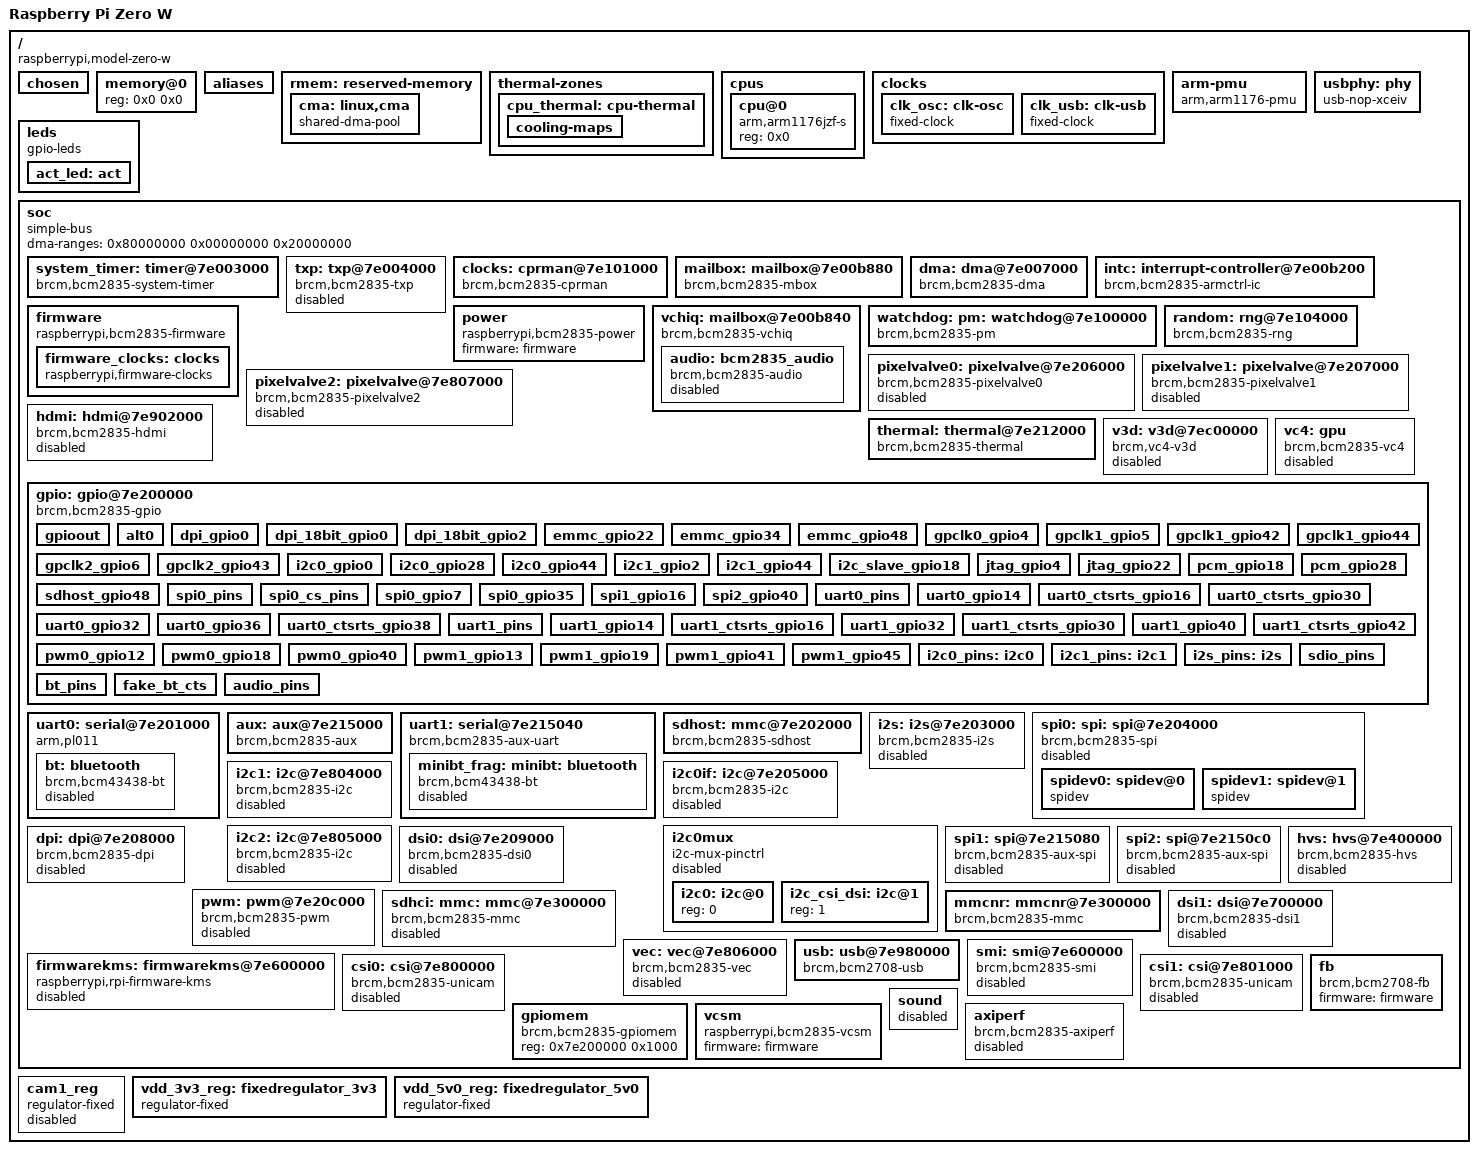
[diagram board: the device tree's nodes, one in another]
/dts-v1/;

#include <dt-bindings/pinctrl/bcm2835.h>
#include <dt-bindings/clock/bcm2835.h>
#include <dt-bindings/clock/bcm2835-aux.h>
#include <dt-bindings/gpio/gpio.h>
#include <dt-bindings/interrupt-controller/irq.h>
#include <dt-bindings/soc/bcm2835-pm.h>

#include <dt-bindings/power/raspberrypi-power.h>

/ {
    compatible = "raspberrypi,model-zero-w", "brcm,bcm2835";
	model = "Raspberry Pi Zero W";
    memreserve = <0x00000000 0x00001000>;
	#address-cells = <1>;
	#size-cells = <1>;
	interrupt-parent = <&intc>;

	chosen {
		bootargs = "coherent_pool=1M 8250.nr_uarts=1 snd_bcm2835.enable_compat_alsa=0 snd_bcm2835.enable_hdmi=1";
	};

	memory@0 {
		device_type = "memory";
		reg = <0x0 0x0>;
	};

    aliases {
		audio = &audio;
		aux = &aux;
		sound = &sound;
		soc = &soc;
		dma = &dma;
		intc = &intc;
		watchdog = &watchdog;
		random = &random;
		mailbox = &mailbox;
		gpio = &gpio;
        serial0 = &uart0;
		serial1 = &uart1;
		uart0 = &uart0;
		uart1 = &uart1;
        sdhost = &sdhost;
		mmc = &mmc;
		mmc1 = &mmcnr;
		mmc0 = &sdhost;
		i2s = &i2s;
		i2c0 = &i2c0;
		i2c1 = &i2c1;
		i2c10 = &i2c_csi_dsi;
        i2c2 = &i2c2;
		spi0 = &spi0;
		spi1 = &spi1;
		spi2 = &spi2;
		usb = &usb;
        leds = &leds;
		fb = &fb;
		thermal = &thermal;
		axiperf = &axiperf;
	};

    rmem: reserved-memory {
		#address-cells = <1>;
		#size-cells = <1>;
		ranges;

		cma: linux,cma {
			compatible = "shared-dma-pool";
			size = <0x4000000>; /* 64MB */
			reusable;
			linux,cma-default;
		};
	};

    thermal-zones {
		cpu_thermal: cpu-thermal {
			polling-delay-passive = <0>;
			polling-delay = <1000>;
            thermal-sensors = <&thermal>;
			coefficients = <(-538)	407000>;

			cooling-maps {
			};
		};
	};

	cpus {
		#address-cells = <1>;
		#size-cells = <0>;

		cpu@0 {
			device_type = "cpu";
			compatible = "arm,arm1176jzf-s";
			reg = <0x0>;
		};
	};

    clocks {
		/* The oscillator is the root of the clock tree. */
		clk_osc: clk-osc {
			compatible = "fixed-clock";
			#clock-cells = <0>;
			clock-output-names = "osc";
			clock-frequency = <19200000>;
		};

		clk_usb: clk-usb {
			compatible = "fixed-clock";
			#clock-cells = <0>;
			clock-output-names = "otg";
			clock-frequency = <480000000>;
		};
	};

	arm-pmu {
		compatible = "arm,arm1176-pmu";
	};

	usbphy: phy {
		compatible = "usb-nop-xceiv";
		#phy-cells = <0>;
	};

	leds: leds {
		compatible = "gpio-leds";

		act_led: act {
			label = "led0";
			default-state = "keep";
			linux,default-trigger = "none";
			gpios = <&gpio 0 0>;
		};
	};

    soc: soc {
		compatible = "simple-bus";
		#address-cells = <1>;
		#size-cells = <1>;

		ranges = <0x7e000000 0x20000000 0x02000000>;
		dma-ranges = <0x80000000 0x00000000 0x20000000>;

		system_timer: timer@7e003000 {
			compatible = "brcm,bcm2835-system-timer";
			reg = <0x7e003000 0x1000>;
			interrupts = <1 0>, <1 1>, <1 2>, <1 3>;
			/* This could be a reference to BCM2835_CLOCK_TIMER,
			 * but we don't have the driver using the common clock
			 * support yet.
			 */
			clock-frequency = <1000000>;
		};

		txp: txp@7e004000 {
			compatible = "brcm,bcm2835-txp";
			reg = <0x7e004000 0x20>;
			interrupts = <1 11>;
			status = "disabled";
		};

		clocks: cprman@7e101000 {
			compatible = "brcm,bcm2835-cprman";
			#clock-cells = <1>;
			reg = <0x7e101000 0x2000>;
			firmware = <&firmware>;

			/* CPRMAN derives almost everything from the
			 * platform's oscillator.  However, the DSI
			 * pixel clocks come from the DSI analog PHY.
			 */
			clocks = <&clk_osc>,
				<&dsi0 0>, <&dsi0 1>, <&dsi0 2>,
				<&dsi1 0>, <&dsi1 1>, <&dsi1 2>;
		};

		mailbox: mailbox@7e00b880 {
			compatible = "brcm,bcm2835-mbox";
			reg = <0x7e00b880 0x40>;
			interrupts = <0 1>;
			#mbox-cells = <0>;
		};

        dma: dma@7e007000 {
			compatible = "brcm,bcm2835-dma";
			reg = <0x7e007000 0xf00>;
			interrupts = <1 16>,
				     <1 17>,
				     <1 18>,
				     <1 19>,
				     <1 20>,
				     <1 21>,
				     <1 22>,
				     <1 23>,
				     <1 24>,
				     <1 25>,
				     <1 26>,
				     /* dma channel 11-14 share one irq */
				     <1 27>,
				     <1 27>,
				     <1 27>,
				     <1 27>,
				     /* unused shared irq for all channels */
				     <1 28>;
			interrupt-names = "dma0",
					  "dma1",
					  "dma2",
					  "dma3",
					  "dma4",
					  "dma5",
					  "dma6",
					  "dma7",
					  "dma8",
					  "dma9",
					  "dma10",
					  "dma11",
					  "dma12",
					  "dma13",
					  "dma14",
					  "dma-shared-all";
			#dma-cells = <1>;
			brcm,dma-channel-mask = <0x7f35>;
		};

		intc: interrupt-controller@7e00b200 {
			compatible = "brcm,bcm2835-armctrl-ic";
			reg = <0x7e00b200 0x200>;
			interrupt-controller;
			#interrupt-cells = <2>;
		};

		firmware: firmware {
			compatible = "raspberrypi,bcm2835-firmware", "simple-mfd";
			#address-cells = <1>;
			#size-cells = <1>;

			mboxes = <&mailbox>;
			dma-ranges;

			firmware_clocks: clocks {
				compatible = "raspberrypi,firmware-clocks";
				#clock-cells = <1>;
			};
		};

		power: power {
			compatible = "raspberrypi,bcm2835-power";
			firmware = <&firmware>;
			#power-domain-cells = <1>;
		};

		vchiq: mailbox@7e00b840 {
			compatible = "brcm,bcm2835-vchiq";
			reg = <0x7e00b840 0x3c>;
			interrupts = <0 2>;
			
			/* Onboard audio */
			audio: bcm2835_audio {
				compatible = "brcm,bcm2835-audio";
				brcm,pwm-channels = <8>;
				status = "disabled";
				pinctrl-names = "default";
				pinctrl-0 = <&audio_pins>;
				brcm,disable-headphones = <1>;
			};
		};

		watchdog: pm: watchdog@7e100000 {
			compatible = "brcm,bcm2835-pm", "brcm,bcm2835-pm-wdt";
			#power-domain-cells = <1>;
			#reset-cells = <1>;
			reg = <0x7e100000 0x114>,
			      <0x7e00a000 0x24>;
			clocks = <&clocks BCM2835_CLOCK_V3D>,
				 <&clocks BCM2835_CLOCK_PERI_IMAGE>,
				 <&clocks BCM2835_CLOCK_H264>,
				 <&clocks BCM2835_CLOCK_ISP>;
			clock-names = "v3d", "peri_image", "h264", "isp";
			system-power-controller;
		};

		random: rng@7e104000 {
			compatible = "brcm,bcm2835-rng";
			reg = <0x7e104000 0x10>;
			interrupts = <2 29>;
		};

		pixelvalve0: pixelvalve@7e206000 {
			compatible = "brcm,bcm2835-pixelvalve0";
			reg = <0x7e206000 0x100>;
			interrupts = <2 13>; /* pwa0 */
			status = "disabled";
		};

		pixelvalve1: pixelvalve@7e207000 {
			compatible = "brcm,bcm2835-pixelvalve1";
			reg = <0x7e207000 0x100>;
			interrupts = <2 14>; /* pwa1 */
			status = "disabled";
		};

		pixelvalve2: pixelvalve@7e807000 {
			compatible = "brcm,bcm2835-pixelvalve2";
			reg = <0x7e807000 0x100>;
			interrupts = <2 10>; /* pixelvalve */
			status = "disabled";
		};

		thermal: thermal@7e212000 {
			compatible = "brcm,bcm2835-thermal";
			reg = <0x7e212000 0x8>;
			clocks = <&clocks BCM2835_CLOCK_TSENS>;
			#thermal-sensor-cells = <0>;
			status = "okay";
		};

		hdmi: hdmi@7e902000 {
			compatible = "brcm,bcm2835-hdmi";
			reg = <0x7e902000 0x600>,
			      <0x7e808000 0x100>;
			reg-names = "hdmi",
				    "hd";
			interrupts = <2 8>, <2 9>;
			ddc = <&i2c2>;
			clocks = <&clocks BCM2835_PLLH_PIX>,
				 <&clocks BCM2835_CLOCK_HSM>;
			clock-names = "pixel", "hdmi";
			dmas = <&dma (17|(1<<27)|(1<<24))>;
			dma-names = "audio-rx";
			power-domains = <&power RPI_POWER_DOMAIN_HDMI>;
			hpd-gpios = <&gpio 46 GPIO_ACTIVE_LOW>;
			status = "disabled";
		};

		v3d: v3d@7ec00000 {
			compatible = "brcm,vc4-v3d";
			reg = <0x7ec00000 0x1000>;
			interrupts = <1 10>;
			power-domains = <&power RPI_POWER_DOMAIN_V3D>;
			status = "disabled";
		};

		vc4: gpu {
			compatible = "brcm,bcm2835-vc4";
			status = "disabled";
		};

		gpio: gpio@7e200000 {
			compatible = "brcm,bcm2835-gpio";
			reg = <0x7e200000 0xb4>;
			/*
			 * The GPIO IP block is designed for 3 banks of GPIOs.
			 * Each bank has a GPIO interrupt for itself.
			 * There is an overall "any bank" interrupt.
			 * In order, these are GIC interrupts 17, 18, 19, 20.
			 * Since the BCM2835 only has 2 banks, the 2nd bank
			 * interrupt output appears to be mirrored onto the
			 * 3rd bank's interrupt signal.
			 * So, a bank0 interrupt shows up on 17, 20, and
			 * a bank1 interrupt shows up on 18, 19, 20!
			 */
			//interrupts = <2 17>, <2 18>, <2 19>, <2 20>;
			interrupts = <2 17>, <2 18>;

			gpio-controller;
			#gpio-cells = <2>;

			interrupt-controller;
			#interrupt-cells = <2>;

			pinctrl-names = "default";

			/* Defines common pin muxing groups
			 *
			 * While each pin can have its mux selected
			 * for various functions individually, some
			 * groups only make sense to switch to a
			 * particular function together.
			 */

			gpioout: gpioout {
				brcm,pins = <6>;
				brcm,function = <BCM2835_FSEL_GPIO_OUT>;
			};

			alt0: alt0 {
				brcm,pins = <4 5 7 8 9 10 11>;
				brcm,function = <BCM2835_FSEL_ALT0>;
			};

			dpi_gpio0: dpi_gpio0 {
				brcm,pins = <0 1 2 3 4 5 6 7 8 9 10 11
					     12 13 14 15 16 17 18 19
					     20 21 22 23 24 25 26 27>;
				brcm,function = <BCM2835_FSEL_ALT2>;
			};
			dpi_18bit_gpio0: dpi_18bit_gpio0 {
				brcm,pins = <0 1 2 3 4 5 6 7 8 9 10 11
						12 13 14 15 16 17 18 19
						20 21>;
				brcm,function = <BCM2835_FSEL_ALT2>;
			};
			dpi_18bit_gpio2: dpi_18bit_gpio2 {
				brcm,pins = <2 3 4 5 6 7 8 9 10 11
						12 13 14 15 16 17 18 19
						20 21>;
				brcm,function = <BCM2835_FSEL_ALT2>;
			};
			emmc_gpio22: emmc_gpio22 {
				brcm,pins = <22 23 24 25 26 27>;
				brcm,function = <BCM2835_FSEL_ALT3>;
			};
			emmc_gpio34: emmc_gpio34 {
				brcm,pins = <34 35 36 37 38 39>;
				brcm,function = <BCM2835_FSEL_ALT3>;
				brcm,pull = <BCM2835_PUD_OFF
					     BCM2835_PUD_UP
					     BCM2835_PUD_UP
					     BCM2835_PUD_UP
					     BCM2835_PUD_UP
					     BCM2835_PUD_UP>;
			};
			emmc_gpio48: emmc_gpio48 {
				brcm,pins = <48 49 50 51 52 53>;
				brcm,function = <BCM2835_FSEL_ALT3>;
			};

			gpclk0_gpio4: gpclk0_gpio4 {
				brcm,pins = <4>;
				brcm,function = <BCM2835_FSEL_ALT0>;
			};
			gpclk1_gpio5: gpclk1_gpio5 {
				brcm,pins = <5>;
				brcm,function = <BCM2835_FSEL_ALT0>;
			};
			gpclk1_gpio42: gpclk1_gpio42 {
				brcm,pins = <42>;
				brcm,function = <BCM2835_FSEL_ALT0>;
			};
			gpclk1_gpio44: gpclk1_gpio44 {
				brcm,pins = <44>;
				brcm,function = <BCM2835_FSEL_ALT0>;
			};
			gpclk2_gpio6: gpclk2_gpio6 {
				brcm,pins = <6>;
				brcm,function = <BCM2835_FSEL_ALT0>;
			};
			gpclk2_gpio43: gpclk2_gpio43 {
				brcm,pins = <43>;
				brcm,function = <BCM2835_FSEL_ALT0>;
				brcm,pull = <BCM2835_PUD_OFF>;
			};

			i2c0_gpio0: i2c0_gpio0 {
				brcm,pins = <0 1>;
				brcm,function = <BCM2835_FSEL_ALT0>;
			};
			i2c0_gpio28: i2c0_gpio28 {
				brcm,pins = <28 29>;
				brcm,function = <BCM2835_FSEL_ALT0>;
			};
			i2c0_gpio44: i2c0_gpio44 {
				brcm,pins = <44 45>;
				brcm,function = <BCM2835_FSEL_ALT1>;
			};
			i2c1_gpio2: i2c1_gpio2 {
				brcm,pins = <2 3>;
				brcm,function = <BCM2835_FSEL_ALT0>;
			};
			i2c1_gpio44: i2c1_gpio44 {
				brcm,pins = <44 45>;
				brcm,function = <BCM2835_FSEL_ALT2>;
			};
			i2c_slave_gpio18: i2c_slave_gpio18 {
				brcm,pins = <18 19 20 21>;
				brcm,function = <BCM2835_FSEL_ALT3>;
			};

			jtag_gpio4: jtag_gpio4 {
				brcm,pins = <4 5 6 12 13>;
				brcm,function = <BCM2835_FSEL_ALT5>;
			};
			jtag_gpio22: jtag_gpio22 {
				brcm,pins = <22 23 24 25 26 27>;
				brcm,function = <BCM2835_FSEL_ALT4>;
			};

			pcm_gpio18: pcm_gpio18 {
				brcm,pins = <18 19 20 21>;
				brcm,function = <BCM2835_FSEL_ALT0>;
			};
			pcm_gpio28: pcm_gpio28 {
				brcm,pins = <28 29 30 31>;
				brcm,function = <BCM2835_FSEL_ALT2>;
			};

			sdhost_gpio48: sdhost_gpio48 {
				brcm,pins = <48 49 50 51 52 53>;
				brcm,function = <BCM2835_FSEL_ALT0>;
			};

			spi0_pins: spi0_pins {
				brcm,pins = <9 10 11>;
				brcm,function = <4>; /* alt0 */
			};
			spi0_cs_pins: spi0_cs_pins {
				brcm,pins = <8 7>;
				brcm,function = <1>; /* output */
			};
			spi0_gpio7: spi0_gpio7 {
				brcm,pins = <7 8 9 10 11>;
				brcm,function = <BCM2835_FSEL_ALT0>;
			};
			spi0_gpio35: spi0_gpio35 {
				brcm,pins = <35 36 37 38 39>;
				brcm,function = <BCM2835_FSEL_ALT0>;
			};
			spi1_gpio16: spi1_gpio16 {
				brcm,pins = <16 17 18 19 20 21>;
				brcm,function = <BCM2835_FSEL_ALT4>;
			};
			spi2_gpio40: spi2_gpio40 {
				brcm,pins = <40 41 42 43 44 45>;
				brcm,function = <BCM2835_FSEL_ALT4>;
			};			

			uart0_pins: uart0_pins {
				brcm,pins = <14 15>;
				brcm,function = <4>; /* alt0 */
				brcm,pull = <0 2>;
			};
			uart0_gpio14: uart0_gpio14 {
				brcm,pins = <14 15>;
				brcm,function = <BCM2835_FSEL_ALT0>;
			};
			/* Separate from the uart0_gpio14 group
			 * because it conflicts with spi1_gpio16, and
			 * people often run uart0 on the two pins
			 * without flow control.
			 */
			uart0_ctsrts_gpio16: uart0_ctsrts_gpio16 {
				brcm,pins = <16 17>;
				brcm,function = <BCM2835_FSEL_ALT3>;
			};
			uart0_ctsrts_gpio30: uart0_ctsrts_gpio30 {
				brcm,pins = <30 31>;
				brcm,function = <BCM2835_FSEL_ALT3>;
				brcm,pull = <BCM2835_PUD_UP BCM2835_PUD_OFF>;
			};
			uart0_gpio32: uart0_gpio32 {
				brcm,pins = <32 33>;
				brcm,function = <BCM2835_FSEL_ALT3>;
				brcm,pull = <BCM2835_PUD_OFF BCM2835_PUD_UP>;
			};
			uart0_gpio36: uart0_gpio36 {
				brcm,pins = <36 37>;
				brcm,function = <BCM2835_FSEL_ALT2>;
			};
			uart0_ctsrts_gpio38: uart0_ctsrts_gpio38 {
				brcm,pins = <38 39>;
				brcm,function = <BCM2835_FSEL_ALT2>;
			};

			uart1_pins: uart1_pins {
				brcm,pins = <32 33>;
				brcm,function = <2>; /* alt5=UART1 */
				brcm,pull = <0 2>;
			};
			uart1_gpio14: uart1_gpio14 {
				brcm,pins = <14 15>;
				brcm,function = <BCM2835_FSEL_ALT5>;
			};
			uart1_ctsrts_gpio16: uart1_ctsrts_gpio16 {
				brcm,pins = <16 17>;
				brcm,function = <BCM2835_FSEL_ALT5>;
			};
			uart1_gpio32: uart1_gpio32 {
				brcm,pins = <32 33>;
				brcm,function = <BCM2835_FSEL_ALT5>;
			};
			uart1_ctsrts_gpio30: uart1_ctsrts_gpio30 {
				brcm,pins = <30 31>;
				brcm,function = <BCM2835_FSEL_ALT5>;
			};
			uart1_gpio40: uart1_gpio40 {
				brcm,pins = <40 41>;
				brcm,function = <BCM2835_FSEL_ALT5>;
			};
			uart1_ctsrts_gpio42: uart1_ctsrts_gpio42 {
				brcm,pins = <42 43>;
				brcm,function = <BCM2835_FSEL_ALT5>;
			};

			pwm0_gpio12: pwm0_gpio12 {
				brcm,pins = <12>;
				brcm,function = <BCM2835_FSEL_ALT0>;
			};
			pwm0_gpio18: pwm0_gpio18 {
				brcm,pins = <18>;
				brcm,function = <BCM2835_FSEL_ALT5>;
			};
			pwm0_gpio40: pwm0_gpio40 {
				brcm,pins = <40>;
				brcm,function = <BCM2835_FSEL_ALT0>;
			};
			pwm1_gpio13: pwm1_gpio13 {
				brcm,pins = <13>;
				brcm,function = <BCM2835_FSEL_ALT0>;
			};
			pwm1_gpio19: pwm1_gpio19 {
				brcm,pins = <19>;
				brcm,function = <BCM2835_FSEL_ALT5>;
			};
			pwm1_gpio41: pwm1_gpio41 {
				brcm,pins = <41>;
				brcm,function = <BCM2835_FSEL_ALT0>;
			};
			pwm1_gpio45: pwm1_gpio45 {
				brcm,pins = <45>;
				brcm,function = <BCM2835_FSEL_ALT0>;
			};

			

			i2c0_pins: i2c0 {
				brcm,pins = <0 1>;
				brcm,function = <4>;
			};

			i2c1_pins: i2c1 {
				brcm,pins = <2 3>;
				brcm,function = <4>;
			};

			i2s_pins: i2s {
				brcm,pins = <18 19 20 21>;
				brcm,function = <4>; /* alt0 */
			};

			sdio_pins: sdio_pins {
				brcm,pins = <34 35 36 37 38 39>;
				brcm,function = <7>; /* ALT3 = SD1 */
				brcm,pull = <0 2 2 2 2 2>;
			};

			bt_pins: bt_pins {
				brcm,pins = <43>;
				brcm,function = <4>; /* alt0:GPCLK2 */
				brcm,pull = <0>; /* none */
			};

			fake_bt_cts: fake_bt_cts {
				brcm,pins = <31>;
				brcm,function = <1>; /* output */
			};

			audio_pins: audio_pins {
				brcm,pins = <>;
				brcm,function = <>;
			};
		};

		uart0: serial@7e201000 {
			compatible = "arm,pl011", "arm,primecell";
			reg = <0x7e201000 0x200>;
			interrupts = <2 25>;
			clocks = <&clocks BCM2835_CLOCK_UART>,
				 <&clocks BCM2835_CLOCK_VPU>;
			clock-names = "uartclk", "apb_pclk";
			arm,primecell-periphid = <0x00241011>;
			/* Enable CTS bug workaround */
			cts-event-workaround;
			skip-init;
			pinctrl-names = "default";
			pinctrl-0 = <&uart0_pins>;
			status = "okay";

			bt: bluetooth {
				compatible = "brcm,bcm43438-bt";
				max-speed = <3000000>;
				shutdown-gpios = <&gpio 45 GPIO_ACTIVE_HIGH>;
				status = "disabled";
			};
		};

		aux: aux@7e215000 {
			compatible = "brcm,bcm2835-aux";
			#clock-cells = <1>;
			reg = <0x7e215000 0x8>;
			clocks = <&clocks BCM2835_CLOCK_VPU>;
		};

		uart1: serial@7e215040 {
			compatible = "brcm,bcm2835-aux-uart";
			reg = <0x7e215040 0x40>;
			interrupts = <1 29>;
			clocks = <&aux BCM2835_AUX_CLOCK_UART>;
			skip-init;
			pinctrl-names = "default";
			pinctrl-0 = <&uart1_pins &bt_pins &fake_bt_cts>;
			status = "okay";

			minibt_frag: minibt: bluetooth {
				compatible = "brcm,bcm43438-bt";
				max-speed = <460800>;
				shutdown-gpios = <&gpio 45 GPIO_ACTIVE_HIGH>;
				status = "disabled";
			};
		};

		sdhost: mmc@7e202000 {
			compatible = "brcm,bcm2835-sdhost";
			reg = <0x7e202000 0x100>;
			interrupts = <2 24>;
			clocks = <&clocks BCM2835_CLOCK_VPU>;
			dmas = <&dma (13|(1<<29))>;
			dma-names = "rx-tx";
			bus-width = <4>;
			brcm,overclock-50 = <0>;
			brcm,pio-limit = <1>;
			pinctrl-names = "default";
			pinctrl-0 = <&sdhost_gpio48>;
			status = "okay";
		};

		i2s: i2s@7e203000 {
			compatible = "brcm,bcm2835-i2s";
			reg = <0x7e203000 0x24>;
			clocks = <&clocks BCM2835_CLOCK_PCM>;
			status = "disabled";
			dmas = <&dma 2>, <&dma 3>;
			dma-names = "tx", "rx";
			#sound-dai-cells = <0>;
			pinctrl-names = "default";
			pinctrl-0 = <&i2s_pins>;
		};

		spi0: spi: spi@7e204000 {
			compatible = "brcm,bcm2835-spi";
			reg = <0x7e204000 0x200>;
			interrupts = <2 22>;
			clocks = <&clocks BCM2835_CLOCK_VPU>;
			#address-cells = <1>;
			#size-cells = <0>;
			status = "disabled";
			dmas = <&dma 6>, <&dma 7>;
			dma-names = "tx", "rx";
			pinctrl-names = "default";
			pinctrl-0 = <&spi0_pins &spi0_cs_pins>;
			cs-gpios = <&gpio 8 1>, <&gpio 7 1>;

			spidev0: spidev@0{
				compatible = "spidev";
				reg = <0>;	/* CE0 */
				#address-cells = <1>;
				#size-cells = <0>;
				spi-max-frequency = <125000000>;
			};

			spidev1: spidev@1{
				compatible = "spidev";
				reg = <1>;	/* CE1 */
				#address-cells = <1>;
				#size-cells = <0>;
				spi-max-frequency = <125000000>;
			};
		};

		i2c0if: i2c@7e205000 {
			compatible = "brcm,bcm2835-i2c";
			reg = <0x7e205000 0x200>;
			interrupts = <2 21>;
			clocks = <&clocks BCM2835_CLOCK_VPU>;
			clock-frequency = <100000>;
			#address-cells = <1>;
			#size-cells = <0>;
			status = "disabled";
		};

		i2c0mux: i2c0mux {
			compatible = "i2c-mux-pinctrl";
			#address-cells = <1>;
			#size-cells = <0>;

			i2c-parent = <&i2c0if>;

			pinctrl-names = "i2c0", "i2c_csi_dsi";
			pinctrl-0 = <&i2c0_gpio0>;
			pinctrl-1 = <&i2c0_gpio28>;
			status = "disabled";

			i2c0: i2c@0 {
				reg = <0>;
				#address-cells = <1>;
				#size-cells = <0>;
			};

			i2c_csi_dsi: i2c@1 {
				reg = <1>;
				#address-cells = <1>;
				#size-cells = <0>;
			};
		};

        i2c1: i2c@7e804000 {
			compatible = "brcm,bcm2835-i2c";
			reg = <0x7e804000 0x1000>;
			interrupts = <2 21>;
			clocks = <&clocks BCM2835_CLOCK_VPU>;
			clock-frequency = <100000>;
			#address-cells = <1>;
			#size-cells = <0>;
			pinctrl-names = "default";
			pinctrl-0 = <&i2c1_pins>;
			status = "disabled";
		};

        i2c2: i2c@7e805000 {
			compatible = "brcm,bcm2835-i2c";
			reg = <0x7e805000 0x1000>;
			interrupts = <2 21>;
			clocks = <&clocks BCM2835_CLOCK_VPU>;
			clock-frequency = <100000>;
			#address-cells = <1>;
			#size-cells = <0>;
			status = "disabled";
		};

		dpi: dpi@7e208000 {
			compatible = "brcm,bcm2835-dpi";
			reg = <0x7e208000 0x8c>;
			clocks = <&clocks BCM2835_CLOCK_VPU>,
				 <&clocks BCM2835_CLOCK_DPI>;
			clock-names = "core", "pixel";
			#address-cells = <1>;
			#size-cells = <0>;
			status = "disabled";
		};

		dsi0: dsi@7e209000 {
			compatible = "brcm,bcm2835-dsi0";
			reg = <0x7e209000 0x78>;
			interrupts = <2 4>;
			#address-cells = <1>;
			#size-cells = <0>;
			#clock-cells = <1>;

			clocks = <&clocks BCM2835_PLLA_DSI0>,
				 <&clocks BCM2835_CLOCK_DSI0E>,
				 <&clocks BCM2835_CLOCK_DSI0P>;
			clock-names = "phy", "escape", "pixel";

			clock-output-names = "dsi0_byte",
					     "dsi0_ddr2",
					     "dsi0_ddr";

			power-domains = <&power RPI_POWER_DOMAIN_DSI0>;
			status = "disabled";
		};

		spi1: spi@7e215080 {
			compatible = "brcm,bcm2835-aux-spi";
			reg = <0x7e215080 0x40>;
			interrupts = <1 29>;
			clocks = <&aux BCM2835_AUX_CLOCK_SPI1>;
			#address-cells = <1>;
			#size-cells = <0>;
			status = "disabled";
		};

		spi2: spi@7e2150c0 {
			compatible = "brcm,bcm2835-aux-spi";
			reg = <0x7e2150c0 0x40>;
			interrupts = <1 29>;
			clocks = <&aux BCM2835_AUX_CLOCK_SPI2>;
			#address-cells = <1>;
			#size-cells = <0>;
			status = "disabled";
		};

		pwm: pwm@7e20c000 {
			compatible = "brcm,bcm2835-pwm";
			reg = <0x7e20c000 0x28>;
			clocks = <&clocks BCM2835_CLOCK_PWM>;
			assigned-clocks = <&clocks BCM2835_CLOCK_PWM>;
			assigned-clock-rates = <10000000>;
			#pwm-cells = <2>;
			status = "disabled";
		};

		sdhci: mmc: mmc@7e300000 {
			compatible = "brcm,bcm2835-mmc", "brcm,bcm2835-sdhci";
			reg = <0x7e300000 0x100>;
			interrupts = <2 30>;
			clocks = <&clocks BCM2835_CLOCK_EMMC>;
			dmas = <&dma 11>;
			dma-names = "rx-tx";
			brcm,overclock-50 = <0>;
			pinctrl-names = "default";
			pinctrl-0 = <&emmc_gpio48>;
			bus-width = <4>;
			status = "disabled";
		};

		/* A clone of mmc but with non-removable set */
		mmcnr: mmcnr@7e300000 {
			compatible = "brcm,bcm2835-mmc", "brcm,bcm2835-sdhci";
			reg = <0x7e300000 0x100>;
			interrupts = <2 30>;
			clocks = <&clocks BCM2835_CLOCK_EMMC>;
			dmas = <&dma 11>;
			dma-names = "rx-tx";
			brcm,overclock-50 = <0>;
			non-removable;
			pinctrl-names = "default";
			pinctrl-0 = <&sdio_pins>;
			bus-width = <4>;
			status = "okay";
		};

		hvs: hvs@7e400000 {
			compatible = "brcm,bcm2835-hvs";
			reg = <0x7e400000 0x6000>;
			interrupts = <2 1>;
			status = "disabled";
		};

		dsi1: dsi@7e700000 {
			compatible = "brcm,bcm2835-dsi1";
			reg = <0x7e700000 0x8c>;
			interrupts = <2 12>;
			#address-cells = <1>;
			#size-cells = <0>;
			#clock-cells = <1>;

			clocks = <&clocks BCM2835_PLLD_DSI1>,
				 <&clocks BCM2835_CLOCK_DSI1E>,
				 <&clocks BCM2835_CLOCK_DSI1P>;
			clock-names = "phy", "escape", "pixel";

			clock-output-names = "dsi1_byte",
					     "dsi1_ddr2",
					     "dsi1_ddr";

			power-domains = <&power RPI_POWER_DOMAIN_DSI1>;
			status = "disabled";
		};

		vec: vec@7e806000 {
			compatible = "brcm,bcm2835-vec";
			reg = <0x7e806000 0x1000>;
			clocks = <&clocks BCM2835_CLOCK_VEC>;
			interrupts = <2 27>;
			power-domains = <&power RPI_POWER_DOMAIN_VEC>;
			status = "disabled";
		};

		usb: usb@7e980000 {
			compatible = "brcm,bcm2708-usb";
			reg = <0x7e980000 0x10000>,
			      <0x7e006000 0x1000>;
			interrupts = <1 9>,
				    	 <2 0>;
			interrupt-names = "usb",
							  "soft";
			#address-cells = <1>;
			#size-cells = <0>;
			clocks = <&clk_usb>;
			clock-names = "otg";
			phys = <&usbphy>;
			phy-names = "usb2-phy";
			power-domains = <&power RPI_POWER_DOMAIN_USB>;
		};

		firmwarekms: firmwarekms@7e600000 {
			compatible = "raspberrypi,rpi-firmware-kms";
			/* SMI interrupt reg */
			reg = <0x7e600000 0x100>;
			interrupts = <2 16>;
			brcm,firmware = <&firmware>;
			status = "disabled";
		};

		smi: smi@7e600000 {
			compatible = "brcm,bcm2835-smi";
			reg = <0x7e600000 0x100>;
			interrupts = <2 16>;
			clocks = <&clocks BCM2835_CLOCK_SMI>;
			assigned-clocks = <&clocks BCM2835_CLOCK_SMI>;
			assigned-clock-rates = <125000000>;
			dmas = <&dma 4>;
			dma-names = "rx-tx";
			status = "disabled";
		};

		csi0: csi@7e800000 {
			compatible = "brcm,bcm2835-unicam";
			reg = <0x7e800000 0x800>,
			      <0x7e802000 0x4>;
			interrupts = <2 6>;
			clocks = <&clocks BCM2835_CLOCK_CAM0>,
				 <&firmware_clocks 4>;
			clock-names = "lp", "vpu";
			power-domains = <&power RPI_POWER_DOMAIN_UNICAM0>;
			#address-cells = <1>;
			#size-cells = <0>;
			#clock-cells = <1>;
			status = "disabled";
		};

		csi1: csi@7e801000 {
			compatible = "brcm,bcm2835-unicam";
			brcm,num-data-lanes = <2>;
			reg = <0x7e801000 0x800>,
			      <0x7e802004 0x4>;
			interrupts = <2 7>;
			clocks = <&clocks BCM2835_CLOCK_CAM1>,
				 <&firmware_clocks 4>;
			clock-names = "lp", "vpu";
			power-domains = <&power RPI_POWER_DOMAIN_UNICAM1>;
			#address-cells = <1>;
			#size-cells = <0>;
			#clock-cells = <1>;
			status = "disabled";
		};

		gpiomem {
			compatible = "brcm,bcm2835-gpiomem";
			reg = <0x7e200000 0x1000>;
		};

		fb: fb {
			compatible = "brcm,bcm2708-fb";
			firmware = <&firmware>;
			status = "okay";
		};

		vcsm: vcsm {
			compatible = "raspberrypi,bcm2835-vcsm";
			firmware = <&firmware>;
			status = "okay";
		};

		/* External sound card */
		sound: sound {
			status = "disabled";
		};

		axiperf: axiperf {
			compatible = "brcm,bcm2835-axiperf";
			reg = <0x7e009800 0x100>,
			      <0x7ee08000 0x100>;
			firmware = <&firmware>;
			status = "disabled";
		};
	};

	cam1_reg: cam1_reg {
		compatible = "regulator-fixed";
		regulator-name = "cam1-reg";
		enable-active-high;
		gpio = <&gpio 44 GPIO_ACTIVE_HIGH>;
		status = "disabled";
	};

	/* Define these notional regulators for use by overlays */
	vdd_3v3_reg: fixedregulator_3v3 {
		compatible = "regulator-fixed";
		regulator-always-on;
		regulator-max-microvolt = <3300000>;
		regulator-min-microvolt = <3300000>;
		regulator-name = "3v3";
	};
	vdd_5v0_reg: fixedregulator_5v0 {
		compatible = "regulator-fixed";
		regulator-always-on;
		regulator-max-microvolt = <5000000>;
		regulator-min-microvolt = <5000000>;
		regulator-name = "5v0";
	};

	__overrides__ {
		cam0-pwdn-ctrl;
		cam0-pwdn;
		cam0-led-ctrl;
		cam0-led;

		arm_freq;

		cache_line_size;

		uart0 = <&uart0>,"status";
		uart1 = <&uart1>,"status";
		i2s = <&i2s>,"status";
		spi = <&spi0>,"status";
		i2c0 = <&i2c0if>,"status",<&i2c0mux>,"status";
		i2c1 = <&i2c1>,"status";
		i2c0_baudrate = <&i2c0if>,"clock-frequency:0";
		i2c1_baudrate = <&i2c1>,"clock-frequency:0";

		audio = <&audio>,"status";
		watchdog = <&watchdog>,"status";
		random = <&random>,"status";
		sd_overclock = <&sdhost>,"brcm,overclock-50:0";
		sd_force_pio = <&sdhost>,"brcm,force-pio?";
		sd_pio_limit = <&sdhost>,"brcm,pio-limit:0";
		sd_debug     = <&sdhost>,"brcm,debug";
		sdio_overclock = <&mmc>,"brcm,overclock-50:0",
				 <&mmcnr>,"brcm,overclock-50:0";
		axiperf      = <&axiperf>,"status";

		i2c2_iknowwhatimdoing = <&i2c2>,"status";
		i2c2_baudrate = <&i2c2>,"clock-frequency:0";
		sd_poll_once = <&sdhost>,"non-removable?";

		krnbt = <&minibt_frag>,"status";
		krnbt_baudrate = <&bt>,"max-speed:0";

		act_led_gpio = <&act_led>,"gpios:4";
		act_led_activelow = <&act_led>,"gpios:8";
		act_led_trigger = <&act_led>,"linux,default-trigger";

		txd0_pin = <&uart0_pins>,"brcm,pins:0";
		rxd0_pin = <&uart0_pins>,"brcm,pins:4";
		pin_func = <&uart0_pins>,"brcm,function:0";
	};
};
